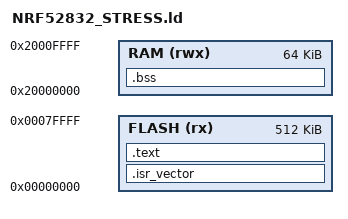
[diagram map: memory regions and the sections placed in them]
/* nRF52832 (xxAA): 512 KB flash, 64 KB RAM (stack at its top) */
MEMORY
{
    FLASH (rx)  : ORIGIN = 0x00000000, LENGTH = 512K
    RAM   (rwx) : ORIGIN = 0x20000000, LENGTH = 64K
}

_estack = ORIGIN(RAM) + LENGTH(RAM);

SECTIONS
{
    .isr_vector : { KEEP(*(.isr_vector)) } > FLASH
    .text       : { *(.text*) *(.rodata*) } > FLASH
    .bss (NOLOAD) : { *(.bss*) *(COMMON) } > RAM
}
